# MKW01Z4 register map
File version: 1.6
MKW01Z4 Freescale Microcontroller
Registers are 32-bit, read-write, reset 0x0 unless marked. A register's access mark holds for its fields unless they carry their own. Offsets are from the block's base; lines under a group give offsets from that group; [hi:lo] are bit positions; {n}, {i} and the like mark numbered series; 'fields as' and 'values as' point back to an identical list; <NAME> marks a mode.

## Memory map
0x00000400 FTFA_FlashConfig size 0xE — Flash configuration field
0x40008000 DMA blocks up to offset 0x140 — DMA Controller
0x40020000 FTFA size 0x14 — Flash Memory Interface
0x40021000 DMAMUX0 size 0x4 — DMA channel multiplexor
0x4002F000 I2S0 size 0x108 — Inter-IC Sound / Synchronous Audio Interface
0x40037000 PIT size 0x120 — Periodic Interrupt Timer
0x40038000 TPM0 size 0x88 — Timer/PWM Module
0x40039000 TPM1 size 0x88 — Timer/PWM Module
0x4003A000 TPM2 size 0x88 — Timer/PWM Module
0x4003B000 ADC0 size 0x70 — Analog-to-Digital Converter
0x4003D000 RTC size 0x20 — Secure Real Time Clock
0x4003F000 DAC0 size 0x24 — 12-Bit Digital-to-Analog Converter
0x40040000 LPTMR0 size 0x10 — Low Power Timer
0x40045000 TSI0 size 0xC — Touch sense input
0x40047000 SIM size 0x1108 — System Integration Module
0x40049000 PORTA size 0xA4 — Pin Control and Interrupts
0x4004A000 PORTB size 0xA4 — Pin Control and Interrupts
0x4004B000 PORTC size 0xA4 — Pin Control and Interrupts
0x4004C000 PORTD size 0xA4 — Pin Control and Interrupts
0x4004D000 PORTE size 0xA4 — Pin Control and Interrupts
0x40064000 MCG size 0x10 — Multipurpose Clock Generator module
0x40065000 OSC0 size 0x1 — Oscillator
0x40066000 I2C0 size 0xC — Inter-Integrated Circuit
0x40067000 I2C1 size 0xC — Inter-Integrated Circuit
0x4006A000 UART0 size 0xC — Universal Asynchronous Receiver/Transmitter
0x4006B000 UART1 size 0x9 — Universal Asynchronous Receiver/Transmitter (UART)
0x4006C000 UART2 size 0x9 — Universal Asynchronous Receiver/Transmitter (UART)
0x40073000 CMP0 size 0x6 — High-Speed Comparator (CMP), Voltage Reference (VREF) Digital-to-Analog Converter (DAC), and Analog Mux (ANMUX)
0x40076000 SPI0 size 0x8 — Serial Peripheral Interface
0x40077000 SPI1 size 0xC — Serial Peripheral Interface
0x4007C000 LLWU size 0xA — Low leakage wakeup unit
0x4007D000 PMC size 0x3 — Power Management Controller
0x4007E000 SMC size 0x4 — System Mode Controller
0x4007F000 RCM size 0x6 — Reset Control Module
0x400FF000 GPIOA size 0x18 — General Purpose Input/Output
0x400FF040 GPIOB size 0x18 — General Purpose Input/Output
0x400FF080 GPIOC size 0x18 — General Purpose Input/Output
0x400FF0C0 GPIOD size 0x18 — General Purpose Input/Output
0x400FF100 GPIOE size 0x18 — General Purpose Input/Output
0xF0000000 MTB size 0x1000 — Micro Trace Buffer
0xF0001000 MTBDWT size 0x1000 — MTB data watchpoint and trace
0xF0002000 ROM size 0x1000 — System ROM
0xF0003000 MCM blocks up to offset 0x44 — Core Platform Miscellaneous Control Module
0xF8000000 FGPIOA size 0x18 — General Purpose Input/Output
0xF8000040 FGPIOB size 0x18 — General Purpose Input/Output
0xF8000080 FGPIOC size 0x18 — General Purpose Input/Output
0xF80000C0 FGPIOD size 0x18 — General Purpose Input/Output
0xF8000100 FGPIOE size 0x18 — General Purpose Input/Output

## Interrupts
0 INT_DMA0 (DMA)
1 INT_DMA1 (DMA)
2 INT_DMA2 (DMA)
3 INT_DMA3 (DMA)
5 INT_FTFA (FTFA)
6 INT_LVD_LVW (PMC)
7 INT_LLWU (LLWU)
8 INT_I2C0 (I2C0)
9 INT_I2C1 (I2C1)
10 INT_SPI0 (SPI0)
11 INT_SPI1 (SPI1)
12 INT_UART0 (UART0)
13 INT_UART1 (UART1)
14 INT_UART2 (UART2)
15 INT_ADC0 (ADC0)
16 INT_CMP0 (CMP0)
17 INT_TPM0 (TPM0)
18 INT_TPM1 (TPM1)
19 INT_TPM2 (TPM2)
20 INT_RTC (RTC)
21 INT_RTC_Seconds (RTC)
22 INT_PIT (PIT)
23 INT_I2S0 (I2S0)
25 INT_DAC0 (DAC0)
26 INT_TSI0 (TSI0)
27 INT_MCG (MCG)
28 INT_LPTMR0 (LPTMR0)
30 INT_PORTA (PORTA, GPIOA)
31 INT_PORTC_PORTD (PORTC, PORTD, GPIOC, GPIOD)

## FTFA_FlashConfig — Flash configuration field
Base 0x00000400; register names take the prefix NV_
0x00 BACKKEY3 8-bit ro reset 0xFF — Backdoor Comparison Key 3.
  [7:0] KEY — Backdoor Comparison Key.
0x01 BACKKEY2 8-bit ro reset 0xFF — Backdoor Comparison Key 2.
  [7:0] KEY — Backdoor Comparison Key.
0x02 BACKKEY1 8-bit ro reset 0xFF — Backdoor Comparison Key 1.
  [7:0] KEY — Backdoor Comparison Key.
0x03 BACKKEY0 8-bit ro reset 0xFF — Backdoor Comparison Key 0.
  [7:0] KEY — Backdoor Comparison Key.
0x04 BACKKEY7 8-bit ro reset 0xFF — Backdoor Comparison Key 7.
  [7:0] KEY — Backdoor Comparison Key.
0x05 BACKKEY6 8-bit ro reset 0xFF — Backdoor Comparison Key 6.
  [7:0] KEY — Backdoor Comparison Key.
0x06 BACKKEY5 8-bit ro reset 0xFF — Backdoor Comparison Key 5.
  [7:0] KEY — Backdoor Comparison Key.
0x07 BACKKEY4 8-bit ro reset 0xFF — Backdoor Comparison Key 4.
  [7:0] KEY — Backdoor Comparison Key.
0x08 FPROT3 8-bit ro reset 0xFF — Non-volatile P-Flash Protection 1 - Low Register
  [7:0] PROT — P-Flash Region Protect
0x09 FPROT2 8-bit ro reset 0xFF — Non-volatile P-Flash Protection 1 - High Register
  [7:0] PROT — P-Flash Region Protect
0x0A FPROT1 8-bit ro reset 0xFF — Non-volatile P-Flash Protection 0 - Low Register
  [7:0] PROT — P-Flash Region Protect
0x0B FPROT0 8-bit ro reset 0xFF — Non-volatile P-Flash Protection 0 - High Register
  [7:0] PROT — P-Flash Region Protect
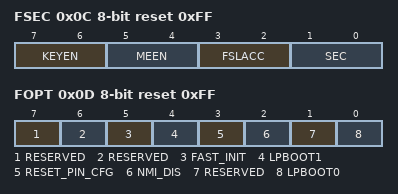
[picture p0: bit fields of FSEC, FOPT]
0x0C FSEC 8-bit ro reset 0xFF — Non-volatile Flash Security Register
  [7:6] KEYEN — Backdoor Key Security Enable
  [5:4] MEEN
  [3:2] FSLACC — Freescale Failure Analysis Access Code
  [1:0] SEC — Flash Security
0x0D FOPT 8-bit ro reset 0xFF — Non-volatile Flash Option Register
  [7] RESERVED, [6] RESERVED, [5] FAST_INIT, [4] LPBOOT1, [3] RESET_PIN_CFG, [2] NMI_DIS, [1] RESERVED, [0] LPBOOT0
